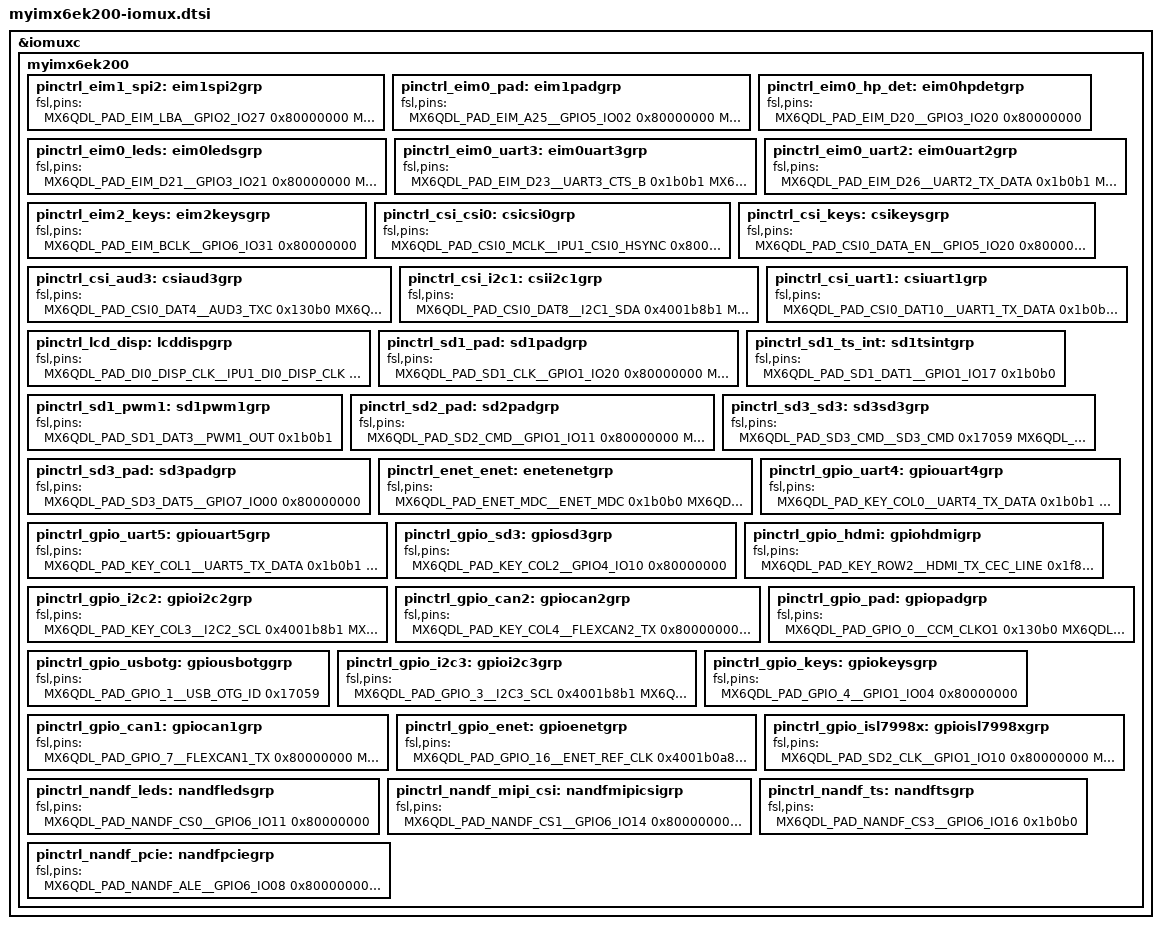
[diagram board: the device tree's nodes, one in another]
/*
 * MYZR Technology Co.,Ltd
 * http://www.myzr.com.cn
 * Tang Bin <tangb@myzr.com.cn>
 */

&iomuxc {
	myimx6ek200 {
		pinctrl_eim1_spi2: eim1spi2grp {
			fsl,pins = <
				/* SPI2_CS1 */
				MX6QDL_PAD_EIM_LBA__GPIO2_IO27  	0x80000000
				MX6QDL_PAD_EIM_OE__ECSPI2_MISO		0x100b1
				/* SPI2_CS0 */
				MX6QDL_PAD_EIM_RW__GPIO2_IO26		0x80000000
				MX6QDL_PAD_EIM_CS0__ECSPI2_SCLK		0x100b1
				MX6QDL_PAD_EIM_CS1__ECSPI2_MOSI		0x100b1
			>;
		};
		/* pinctrl_eim1_nc: eim1ncgrp {
			fsl,pins = <
				MX6QDL_PAD_EIM_A16
				MX6QDL_PAD_EIM_A17
				MX6QDL_PAD_EIM_A18
				MX6QDL_PAD_EIM_A19
				MX6QDL_PAD_EIM_A20
				MX6QDL_PAD_EIM_A21
				MX6QDL_PAD_EIM_A22
				MX6QDL_PAD_EIM_A23
				MX6QDL_PAD_EIM_A24
			>;
		}; */
		
		pinctrl_eim0_pad: eim1padgrp {
			fsl,pins = <
				MX6QDL_PAD_EIM_A25__GPIO5_IO02		0x80000000
				MX6QDL_PAD_EIM_D30__GPIO3_IO30		0x80000000
				/* MX6QDL_PAD_EIM_EB3 */
			>;
		};
		pinctrl_eim0_hp_det: eim0hpdetgrp {
			fsl,pins = <
				MX6QDL_PAD_EIM_D20__GPIO3_IO20  	0x80000000
			>;
		};
		pinctrl_eim0_leds: eim0ledsgrp {
			fsl,pins = <
				MX6QDL_PAD_EIM_D21__GPIO3_IO21		0x80000000
				MX6QDL_PAD_EIM_D22__GPIO3_IO22		0x80000000
			>;
		};
		pinctrl_eim0_uart3: eim0uart3grp {
			fsl,pins = <
				MX6QDL_PAD_EIM_D23__UART3_CTS_B		0x1b0b1
				MX6QDL_PAD_EIM_D24__UART3_TX_DATA	0x1b0b1
				MX6QDL_PAD_EIM_D25__UART3_RX_DATA	0x1b0b1
				MX6QDL_PAD_EIM_D31__UART3_RTS_B		0x1b0b1
			>;
		};
		pinctrl_eim0_uart2: eim0uart2grp {
			fsl,pins = <
				MX6QDL_PAD_EIM_D26__UART2_TX_DATA	0x1b0b1
				MX6QDL_PAD_EIM_D27__UART2_RX_DATA	0x1b0b1
				MX6QDL_PAD_EIM_D28__UART2_CTS_B		0x1b0b1
				MX6QDL_PAD_EIM_D29__UART2_RTS_B		0x1b0b1
			>;
		};
		
		pinctrl_eim2_keys: eim2keysgrp {
			fsl,pins = <
				MX6QDL_PAD_EIM_BCLK__GPIO6_IO31 	0x80000000
			>;
		};
		/* pinctrl_eim2_nc: eim2ncgrp {
			fsl,pins = <
				MX6QDL_PAD_EIM_WAIT
				MX6QDL_PAD_EIM_EB0
				MX6QDL_PAD_EIM_EB1
				MX6QDL_PAD_EIM_DA0
				MX6QDL_PAD_EIM_DA1
				MX6QDL_PAD_EIM_DA2
				MX6QDL_PAD_EIM_DA3
				MX6QDL_PAD_EIM_DA4
				MX6QDL_PAD_EIM_DA5
				MX6QDL_PAD_EIM_DA6
				MX6QDL_PAD_EIM_DA7
				MX6QDL_PAD_EIM_DA8
				MX6QDL_PAD_EIM_DA9
				MX6QDL_PAD_EIM_DA10
				MX6QDL_PAD_EIM_DA11
				MX6QDL_PAD_EIM_DA12
				MX6QDL_PAD_EIM_DA13
				MX6QDL_PAD_EIM_DA14
				MX6QDL_PAD_EIM_DA15
			>;
		}; */
		
		pinctrl_csi_csi0: csicsi0grp {
			fsl,pins = <
				MX6QDL_PAD_CSI0_MCLK__IPU1_CSI0_HSYNC      0x80000000
				MX6QDL_PAD_CSI0_PIXCLK__IPU1_CSI0_PIXCLK   0x80000000
				MX6QDL_PAD_CSI0_VSYNC__IPU1_CSI0_VSYNC     0x80000000
				MX6QDL_PAD_CSI0_DAT12__IPU1_CSI0_DATA12    0x80000000
				MX6QDL_PAD_CSI0_DAT13__IPU1_CSI0_DATA13    0x80000000
				MX6QDL_PAD_CSI0_DAT14__IPU1_CSI0_DATA14    0x80000000
				MX6QDL_PAD_CSI0_DAT15__IPU1_CSI0_DATA15    0x80000000
				MX6QDL_PAD_CSI0_DAT16__IPU1_CSI0_DATA16    0x80000000
				MX6QDL_PAD_CSI0_DAT17__IPU1_CSI0_DATA17    0x80000000
				MX6QDL_PAD_CSI0_DAT18__IPU1_CSI0_DATA18    0x80000000
				MX6QDL_PAD_CSI0_DAT19__IPU1_CSI0_DATA19    0x80000000
			>;
		};
		pinctrl_csi_keys: csikeysgrp {
			fsl,pins = <
				MX6QDL_PAD_CSI0_DATA_EN__GPIO5_IO20			0x80000000
			>;
		};
		pinctrl_csi_aud3: csiaud3grp {
			fsl,pins = <
				MX6QDL_PAD_CSI0_DAT4__AUD3_TXC				0x130b0
				MX6QDL_PAD_CSI0_DAT5__AUD3_TXD				0x110b0
				MX6QDL_PAD_CSI0_DAT6__AUD3_TXFS				0x130b0
				MX6QDL_PAD_CSI0_DAT7__AUD3_RXD				0x130b0
			>;
		};
		pinctrl_csi_i2c1: csii2c1grp {
			fsl,pins = <
				MX6QDL_PAD_CSI0_DAT8__I2C1_SDA				0x4001b8b1
				MX6QDL_PAD_CSI0_DAT9__I2C1_SCL				0x4001b8b1
			>;
		};
		pinctrl_csi_uart1: csiuart1grp {
			fsl,pins = <
				MX6QDL_PAD_CSI0_DAT10__UART1_TX_DATA		0x1b0b1
				MX6QDL_PAD_CSI0_DAT11__UART1_RX_DATA		0x1b0b1
			>;
		};
		
		pinctrl_lcd_disp: lcddispgrp {
			fsl,pins = <
				MX6QDL_PAD_DI0_DISP_CLK__IPU1_DI0_DISP_CLK 0x10
				MX6QDL_PAD_DI0_PIN2__IPU1_DI0_PIN02        0x10
				MX6QDL_PAD_DI0_PIN3__IPU1_DI0_PIN03        0x10
				/* MX6QDL_PAD_DI0_PIN4 */
				MX6QDL_PAD_DI0_PIN15__IPU1_DI0_PIN15       0x10	
				MX6QDL_PAD_DISP0_DAT0__IPU1_DISP0_DATA00   0x10
				MX6QDL_PAD_DISP0_DAT1__IPU1_DISP0_DATA01   0x10
				MX6QDL_PAD_DISP0_DAT2__IPU1_DISP0_DATA02   0x10
				MX6QDL_PAD_DISP0_DAT3__IPU1_DISP0_DATA03   0x10
				MX6QDL_PAD_DISP0_DAT4__IPU1_DISP0_DATA04   0x10
				MX6QDL_PAD_DISP0_DAT5__IPU1_DISP0_DATA05   0x10
				MX6QDL_PAD_DISP0_DAT6__IPU1_DISP0_DATA06   0x10
				MX6QDL_PAD_DISP0_DAT7__IPU1_DISP0_DATA07   0x10
				MX6QDL_PAD_DISP0_DAT8__IPU1_DISP0_DATA08   0x10
				MX6QDL_PAD_DISP0_DAT9__IPU1_DISP0_DATA09   0x10
				MX6QDL_PAD_DISP0_DAT10__IPU1_DISP0_DATA10  0x10
				MX6QDL_PAD_DISP0_DAT11__IPU1_DISP0_DATA11  0x10
				MX6QDL_PAD_DISP0_DAT12__IPU1_DISP0_DATA12  0x10
				MX6QDL_PAD_DISP0_DAT13__IPU1_DISP0_DATA13  0x10
				MX6QDL_PAD_DISP0_DAT14__IPU1_DISP0_DATA14  0x10
				MX6QDL_PAD_DISP0_DAT15__IPU1_DISP0_DATA15  0x10
				MX6QDL_PAD_DISP0_DAT16__IPU1_DISP0_DATA16  0x10
				MX6QDL_PAD_DISP0_DAT17__IPU1_DISP0_DATA17  0x10
				MX6QDL_PAD_DISP0_DAT18__IPU1_DISP0_DATA18  0x10
				MX6QDL_PAD_DISP0_DAT19__IPU1_DISP0_DATA19  0x10
				MX6QDL_PAD_DISP0_DAT20__IPU1_DISP0_DATA20  0x10
				MX6QDL_PAD_DISP0_DAT21__IPU1_DISP0_DATA21  0x10
				MX6QDL_PAD_DISP0_DAT22__IPU1_DISP0_DATA22  0x10
				MX6QDL_PAD_DISP0_DAT23__IPU1_DISP0_DATA23  0x10
			>;
		};
		
		pinctrl_sd1_pad: sd1padgrp {
			fsl,pins = <
				/* MX6QDL_PAD_SD1_CMD */
				MX6QDL_PAD_SD1_CLK__GPIO1_IO20		0x80000000
				MX6QDL_PAD_SD1_DAT0__GPIO1_IO16     0x80000000
				MX6QDL_PAD_SD1_DAT2__GPIO1_IO19		0x80000000
			>;
		};
		pinctrl_sd1_ts_int: sd1tsintgrp {
			fsl,pins = <
				MX6QDL_PAD_SD1_DAT1__GPIO1_IO17		0x1b0b0
			>;
		};
		pinctrl_sd1_pwm1: sd1pwm1grp {
			fsl,pins = <
				MX6QDL_PAD_SD1_DAT3__PWM1_OUT		0x1b0b1
			>;
		};

		pinctrl_sd2_pad: sd2padgrp {
			fsl,pins = <
				MX6QDL_PAD_SD2_CMD__GPIO1_IO11		0x80000000
				MX6QDL_PAD_SD2_CLK__GPIO1_IO10		0x80000000
				MX6QDL_PAD_SD2_DAT0__GPIO1_IO15		0x80000000
				MX6QDL_PAD_SD2_DAT1__GPIO1_IO14		0x80000000
				MX6QDL_PAD_SD2_DAT2__GPIO1_IO13		0x80000000
				MX6QDL_PAD_SD2_DAT3__GPIO1_IO12		0x80000000
			>;
		};
		
		pinctrl_sd3_sd3: sd3sd3grp {
			fsl,pins = <
				MX6QDL_PAD_SD3_CMD__SD3_CMD			0x17059
				MX6QDL_PAD_SD3_CLK__SD3_CLK			0x10059
				MX6QDL_PAD_SD3_DAT0__SD3_DATA0		0x17059
				MX6QDL_PAD_SD3_DAT1__SD3_DATA1		0x17059
				MX6QDL_PAD_SD3_DAT2__SD3_DATA2		0x17059
				MX6QDL_PAD_SD3_DAT3__SD3_DATA3		0x17059
				MX6QDL_PAD_SD3_RST__GPIO7_IO08		0x80000000
			>;
		};
		pinctrl_sd3_pad: sd3padgrp {
			fsl,pins = <
				/* MX6QDL_PAD_SD3_DAT4 */
				MX6QDL_PAD_SD3_DAT5__GPIO7_IO00		0x80000000
				/* MX6QDL_PAD_SD3_DAT6 */
				/* MX6QDL_PAD_SD3_DAT7 */
			>;
		};
		
		pinctrl_enet_enet: enetenetgrp {
			fsl,pins = <
				MX6QDL_PAD_ENET_MDC__ENET_MDC		0x1b0b0
				MX6QDL_PAD_ENET_MDIO__ENET_MDIO		0x1b0b0
				MX6QDL_PAD_ENET_CRS_DV__ENET_RX_EN	0x1b0b0
				/* ENET RST */
				MX6QDL_PAD_ENET_REF_CLK__GPIO1_IO23 0x80000000
				MX6QDL_PAD_ENET_RX_ER__ENET_RX_ER	0x1b0b0
				MX6QDL_PAD_ENET_TX_EN__ENET_TX_EN	0x1b0b0
				MX6QDL_PAD_ENET_RXD0__ENET_RX_DATA0	0x1b0b0
				MX6QDL_PAD_ENET_RXD1__ENET_RX_DATA1	0x1b0b0
				MX6QDL_PAD_ENET_TXD0__ENET_TX_DATA0	0x1b0b0
				MX6QDL_PAD_ENET_TXD1__ENET_TX_DATA1	0x1b0b0
			>;
		};
		
		pinctrl_gpio_uart4: gpiouart4grp {
			fsl,pins = <
				MX6QDL_PAD_KEY_COL0__UART4_TX_DATA		0x1b0b1
				MX6QDL_PAD_KEY_ROW0__UART4_RX_DATA		0x1b0b1
			>;
		};
		pinctrl_gpio_uart5: gpiouart5grp {
			fsl,pins = <
				MX6QDL_PAD_KEY_COL1__UART5_TX_DATA		0x1b0b1
				MX6QDL_PAD_KEY_ROW1__UART5_RX_DATA		0x1b0b1
			>;
		};
		pinctrl_gpio_sd3: gpiosd3grp {
			fsl,pins = <
				MX6QDL_PAD_KEY_COL2__GPIO4_IO10 		0x80000000
			>;
		};
		pinctrl_gpio_hdmi: gpiohdmigrp {
			fsl,pins = <
				MX6QDL_PAD_KEY_ROW2__HDMI_TX_CEC_LINE	0x1f8b0
			>;
		};
		pinctrl_gpio_i2c2: gpioi2c2grp {
			fsl,pins = <
				MX6QDL_PAD_KEY_COL3__I2C2_SCL			0x4001b8b1
				MX6QDL_PAD_KEY_ROW3__I2C2_SDA			0x4001b8b1
			 >;
		};
		pinctrl_gpio_can2: gpiocan2grp {
			fsl,pins = <
				MX6QDL_PAD_KEY_COL4__FLEXCAN2_TX 		0x80000000
				MX6QDL_PAD_KEY_ROW4__FLEXCAN2_RX 		0x80000000
			 >;
		};
		pinctrl_gpio_pad: gpiopadgrp {
			fsl,pins = <
				MX6QDL_PAD_GPIO_0__CCM_CLKO1    	0x130b0
				/* MX6QDL_PAD_GPIO_2 */
				/* MX6QDL_PAD_GPIO_5 */
				MX6QDL_PAD_GPIO_9__WDOG1_B			0x80000000
				/* MX6QDL_PAD_GPIO_17 */
				MX6QDL_PAD_GPIO_19__GPIO4_IO05		0x80000000
			 >;
		};
		pinctrl_gpio_usbotg: gpiousbotggrp {
			fsl,pins = <
				MX6QDL_PAD_GPIO_1__USB_OTG_ID	0x17059
			 >;
		};
		pinctrl_gpio_i2c3: gpioi2c3grp {
			fsl,pins = <
				MX6QDL_PAD_GPIO_3__I2C3_SCL		0x4001b8b1
				MX6QDL_PAD_GPIO_6__I2C3_SDA		0x4001b8b1
			 >;
		};
		pinctrl_gpio_keys: gpiokeysgrp {
			fsl,pins = <
				MX6QDL_PAD_GPIO_4__GPIO1_IO04  		0x80000000
			 >;
		};
		pinctrl_gpio_can1: gpiocan1grp {
			fsl,pins = <
				MX6QDL_PAD_GPIO_7__FLEXCAN1_TX   0x80000000
				MX6QDL_PAD_GPIO_8__FLEXCAN1_RX   0x80000000
			 >;
		};
		pinctrl_gpio_enet: gpioenetgrp {
			fsl,pins = <
				MX6QDL_PAD_GPIO_16__ENET_REF_CLK	0x4001b0a8
				MX6QDL_PAD_GPIO_18__GPIO7_IO13			0x000b1
			 >;
		};

		pinctrl_gpio_isl7998x: gpioisl7998xgrp {
			fsl,pins = <
				/* ISL7998X_RST */
				MX6QDL_PAD_SD2_CLK__GPIO1_IO10		0x80000000
				/* ISL7998X_INT */
				MX6QDL_PAD_SD2_CMD__GPIO1_IO11		0x80000000
				/* ISL7998X_PD */
				MX6QDL_PAD_SD2_DAT3__GPIO1_IO12		0x80000000
				/* ISL7998X_MPP1 */
				MX6QDL_PAD_SD2_DAT1__GPIO1_IO14		0x80000000
				/* ISL7998X_MPP2 */
				MX6QDL_PAD_SD2_DAT0__GPIO1_IO15		0x80000000
			>;
		};
		pinctrl_nandf_leds: nandfledsgrp {
			fsl,pins = <
				MX6QDL_PAD_NANDF_CS0__GPIO6_IO11	0x80000000
			>;
		};
		pinctrl_nandf_mipi_csi: nandfmipicsigrp {
			fsl,pins = <
				MX6QDL_PAD_NANDF_CS1__GPIO6_IO14	0x80000000
				MX6QDL_PAD_NANDF_CS2__GPIO6_IO15	0x80000000
			>;
		};
		pinctrl_nandf_ts: nandftsgrp {
			fsl,pins = <
				/* Reset */
				MX6QDL_PAD_NANDF_CS3__GPIO6_IO16	0x1b0b0
			>;
		};
		pinctrl_nandf_pcie: nandfpciegrp {
			fsl,pins = <
				MX6QDL_PAD_NANDF_ALE__GPIO6_IO08	0x80000000
				MX6QDL_PAD_NANDF_CLE__GPIO6_IO07	0x80000000
				MX6QDL_PAD_NANDF_WP_B__GPIO6_IO09	0x80000000
			>;
		};
		/* pinctrl_nandf_nc: nandfncgrp {
			fsl,pins = <
				MX6QDL_PAD_NANDF_RB0
				MX6QDL_PAD_NANDF_D0
				MX6QDL_PAD_NANDF_D1
				MX6QDL_PAD_NANDF_D2
				MX6QDL_PAD_NANDF_D3
				MX6QDL_PAD_NANDF_D4
				MX6QDL_PAD_NANDF_D5
				MX6QDL_PAD_NANDF_D6
				MX6QDL_PAD_NANDF_D7
			>;
		}; */
		
		/* pinctrl_rgmii_nc: rgmiincgrp {
			fsl,pins = <
				MX6QDL_PAD_RGMII_RD0
				MX6QDL_PAD_RGMII_RD1
				MX6QDL_PAD_RGMII_RD2
				MX6QDL_PAD_RGMII_RD3
				MX6QDL_PAD_RGMII_RXC
				MX6QDL_PAD_RGMII_RX_CTL
				MX6QDL_PAD_RGMII_TD0
				MX6QDL_PAD_RGMII_TD1
				MX6QDL_PAD_RGMII_TD2
				MX6QDL_PAD_RGMII_TD3
				MX6QDL_PAD_RGMII_TXC
				MX6QDL_PAD_RGMII_TX_CTL
			>;
		}; */
	};
};
